# STC32G144K246 register map
Vendor: STC; File version: 2.0
Registers are 8-bit, read-write, no defined reset value unless marked. A register's access mark holds for its fields unless they carry their own. Offsets are from the block's base; [hi:lo] are bit positions; {n}, {i} and the like mark numbered series.

## GPIO9 — P9 端口、模式、上下拉和中断
Base 0x007EF701
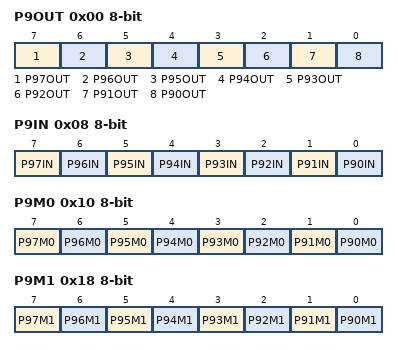
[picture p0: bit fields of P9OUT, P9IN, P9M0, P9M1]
0x00 P9OUT — P9端口输出寄存器
  [all] fields
    0=低电平; 1=高电平
  [7] P97OUT — 设置 P9.7 的输出缓冲区电平。实际输出行为由端口模式及外设复用共同决定。
  [6] P96OUT — 设置 P9.6 的输出缓冲区电平。实际输出行为由端口模式及外设复用共同决定。
  [5] P95OUT — 设置 P9.5 的输出缓冲区电平。实际输出行为由端口模式及外设复用共同决定。
  [4] P94OUT — 设置 P9.4 的输出缓冲区电平。实际输出行为由端口模式及外设复用共同决定。
  [3] P93OUT — 设置 P9.3 的输出缓冲区电平。实际输出行为由端口模式及外设复用共同决定。
  [2] P92OUT — 设置 P9.2 的输出缓冲区电平。实际输出行为由端口模式及外设复用共同决定。
  [1] P91OUT — 设置 P9.1 的输出缓冲区电平。实际输出行为由端口模式及外设复用共同决定。
  [0] P90OUT — 设置 P9.0 的输出缓冲区电平。实际输出行为由端口模式及外设复用共同决定。
0x08 P9IN ro — P9端口输入寄存器
  [all] fields
    0=低电平; 1=高电平
  [7] P97IN — 读取 P9.7 管脚上的实际电平。
  [6] P96IN — 读取 P9.6 管脚上的实际电平。
  [5] P95IN — 读取 P9.5 管脚上的实际电平。
  [4] P94IN — 读取 P9.4 管脚上的实际电平。
  [3] P93IN — 读取 P9.3 管脚上的实际电平。
  [2] P92IN — 读取 P9.2 管脚上的实际电平。
  [1] P91IN — 读取 P9.1 管脚上的实际电平。
  [0] P90IN — 读取 P9.0 管脚上的实际电平。
0x10 P9M0 — P9端口配置寄存器0
  [7] P97M0 — 控制 P9.7 的端口模式低位；与 P9M1.B7 配合设置，组合含义见下表。
  [6] P96M0 — 控制 P9.6 的端口模式低位；与 P9M1.B6 配合设置，组合含义见下表。
  [5] P95M0 — 控制 P9.5 的端口模式低位；与 P9M1.B5 配合设置，组合含义见下表。
  [4] P94M0 — 控制 P9.4 的端口模式低位；与 P9M1.B4 配合设置，组合含义见下表。
  [3] P93M0 — 控制 P9.3 的端口模式低位；与 P9M1.B3 配合设置，组合含义见下表。
  [2] P92M0 — 控制 P9.2 的端口模式低位；与 P9M1.B2 配合设置，组合含义见下表。
  [1] P91M0 — 控制 P9.1 的端口模式低位；与 P9M1.B1 配合设置，组合含义见下表。
  [0] P90M0 — 控制 P9.0 的端口模式低位；与 P9M1.B0 配合设置，组合含义见下表。
0x18 P9M1 — P9端口配置寄存器1
  [7] P97M1 — 控制 P9.7 的端口模式高位；与 P9M0.B7 配合设置，组合含义见下表。
  [6] P96M1 — 控制 P9.6 的端口模式高位；与 P9M0.B6 配合设置，组合含义见下表。
  [5] P95M1 — 控制 P9.5 的端口模式高位；与 P9M0.B5 配合设置，组合含义见下表。
  [4] P94M1 — 控制 P9.4 的端口模式高位；与 P9M0.B4 配合设置，组合含义见下表。
  [3] P93M1 — 控制 P9.3 的端口模式高位；与 P9M0.B3 配合设置，组合含义见下表。
  [2] P92M1 — 控制 P9.2 的端口模式高位；与 P9M0.B2 配合设置，组合含义见下表。
  [1] P91M1 — 控制 P9.1 的端口模式高位；与 P9M0.B1 配合设置，组合含义见下表。
  [0] P90M1 — 控制 P9.0 的端口模式高位；与 P9M0.B0 配合设置，组合含义见下表。
0x20 P9SETB wo write-1-sets — P9 输出置位命令。按位写 1 置位，写 0 不动作。固件写入已验证；Link1D SWD 直写可能改动其他位，请勿在调试器中写入。
0x28 P9CLRB wo write-1-clears — P9 输出清零命令。按位写 1 清零，写 0 不动作。固件写入已验证；Link1D SWD 直写可能改动其他位，请勿在调试器中写入。
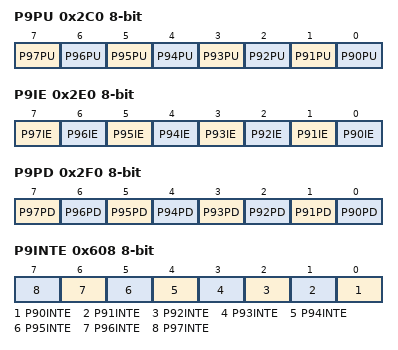
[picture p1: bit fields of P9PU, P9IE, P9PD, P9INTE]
0x2C0 P9PU — P9口上拉电阻控制寄存器
  [all] fields
    0=禁止内部上拉电阻; 1=使能内部上拉电阻
  [7] P97PU — 控制 P9.7 的内部上拉电阻。
  [6] P96PU — 控制 P9.6 的内部上拉电阻。
  [5] P95PU — 控制 P9.5 的内部上拉电阻。
  [4] P94PU — 控制 P9.4 的内部上拉电阻。
  [3] P93PU — 控制 P9.3 的内部上拉电阻。
  [2] P92PU — 控制 P9.2 的内部上拉电阻。
  [1] P91PU — 控制 P9.1 的内部上拉电阻。
  [0] P90PU — 控制 P9.0 的内部上拉电阻。
0x2E0 P9IE — P9口输入使能控制寄存器
  [all] fields
    0=禁止数字信号输入，用于模拟功能; 1=使能数字信号输入
  [7] P97IE — 控制 P9.7 的数字信号输入。
  [6] P96IE — 控制 P9.6 的数字信号输入。
  [5] P95IE — 控制 P9.5 的数字信号输入。
  [4] P94IE — 控制 P9.4 的数字信号输入。
  [3] P93IE — 控制 P9.3 的数字信号输入。
  [2] P92IE — 控制 P9.2 的数字信号输入。
  [1] P91IE — 控制 P9.1 的数字信号输入。
  [0] P90IE — 控制 P9.0 的数字信号输入。
0x2F0 P9PD — P9口下拉电阻控制寄存器
  [all] fields
    0=禁止内部下拉电阻; 1=使能内部下拉电阻
  [7] P97PD — 控制 P9.7 的内部下拉电阻。
  [6] P96PD — 控制 P9.6 的内部下拉电阻。
  [5] P95PD — 控制 P9.5 的内部下拉电阻。
  [4] P94PD — 控制 P9.4 的内部下拉电阻。
  [3] P93PD — 控制 P9.3 的内部下拉电阻。
  [2] P92PD — 控制 P9.2 的内部下拉电阻。
  [1] P91PD — 控制 P9.1 的内部下拉电阻。
  [0] P90PD — 控制 P9.0 的内部下拉电阻。
0x608 P9INTE — P9口中断使能寄存器
  [n-90] P{n}INTE (n=90..97) — 尚未自动匹配到此字段的独立说明；请查看下方章节说明。
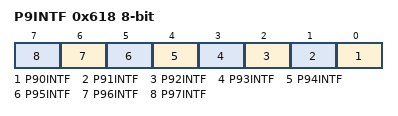
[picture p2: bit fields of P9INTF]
0x618 P9INTF ro — P9口中断标志寄存器
  [n-90] P{n}INTF (n=90..97) — 尚未自动匹配到此字段的独立说明；请查看下方章节说明。

## GPIOA — PA 端口、模式、上下拉和中断
Base 0x007EF702
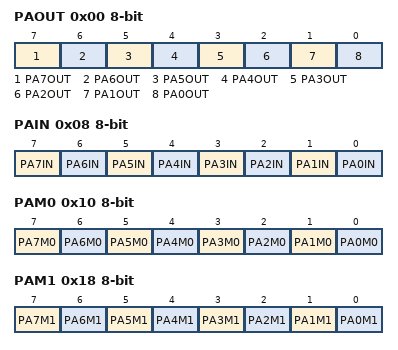
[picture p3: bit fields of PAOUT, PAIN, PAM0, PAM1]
0x00 PAOUT — PA端口输出寄存器
  [all] fields
    0=低电平; 1=高电平
  [7] PA7OUT — 设置 PA.7 的输出缓冲区电平。实际输出行为由端口模式及外设复用共同决定。
  [6] PA6OUT — 设置 PA.6 的输出缓冲区电平。实际输出行为由端口模式及外设复用共同决定。
  [5] PA5OUT — 设置 PA.5 的输出缓冲区电平。实际输出行为由端口模式及外设复用共同决定。
  [4] PA4OUT — 设置 PA.4 的输出缓冲区电平。实际输出行为由端口模式及外设复用共同决定。
  [3] PA3OUT — 设置 PA.3 的输出缓冲区电平。实际输出行为由端口模式及外设复用共同决定。
  [2] PA2OUT — 设置 PA.2 的输出缓冲区电平。实际输出行为由端口模式及外设复用共同决定。
  [1] PA1OUT — 设置 PA.1 的输出缓冲区电平。实际输出行为由端口模式及外设复用共同决定。
  [0] PA0OUT — 设置 PA.0 的输出缓冲区电平。实际输出行为由端口模式及外设复用共同决定。
0x08 PAIN ro — PA端口输入寄存器
  [all] fields
    0=低电平; 1=高电平
  [7] PA7IN — 读取 PA.7 管脚上的实际电平。
  [6] PA6IN — 读取 PA.6 管脚上的实际电平。
  [5] PA5IN — 读取 PA.5 管脚上的实际电平。
  [4] PA4IN — 读取 PA.4 管脚上的实际电平。
  [3] PA3IN — 读取 PA.3 管脚上的实际电平。
  [2] PA2IN — 读取 PA.2 管脚上的实际电平。
  [1] PA1IN — 读取 PA.1 管脚上的实际电平。
  [0] PA0IN — 读取 PA.0 管脚上的实际电平。
0x10 PAM0 — PA端口配置寄存器0
  [7] PA7M0 — 控制 PA.7 的端口模式低位；与 PAM1.B7 配合设置，组合含义见下表。
  [6] PA6M0 — 控制 PA.6 的端口模式低位；与 PAM1.B6 配合设置，组合含义见下表。
  [5] PA5M0 — 控制 PA.5 的端口模式低位；与 PAM1.B5 配合设置，组合含义见下表。
  [4] PA4M0 — 控制 PA.4 的端口模式低位；与 PAM1.B4 配合设置，组合含义见下表。
  [3] PA3M0 — 控制 PA.3 的端口模式低位；与 PAM1.B3 配合设置，组合含义见下表。
  [2] PA2M0 — 控制 PA.2 的端口模式低位；与 PAM1.B2 配合设置，组合含义见下表。
  [1] PA1M0 — 控制 PA.1 的端口模式低位；与 PAM1.B1 配合设置，组合含义见下表。
  [0] PA0M0 — 控制 PA.0 的端口模式低位；与 PAM1.B0 配合设置，组合含义见下表。
0x18 PAM1 — PA端口配置寄存器1
  [7] PA7M1 — 控制 PA.7 的端口模式高位；与 PAM0.B7 配合设置，组合含义见下表。
  [6] PA6M1 — 控制 PA.6 的端口模式高位；与 PAM0.B6 配合设置，组合含义见下表。
  [5] PA5M1 — 控制 PA.5 的端口模式高位；与 PAM0.B5 配合设置，组合含义见下表。
  [4] PA4M1 — 控制 PA.4 的端口模式高位；与 PAM0.B4 配合设置，组合含义见下表。
  [3] PA3M1 — 控制 PA.3 的端口模式高位；与 PAM0.B3 配合设置，组合含义见下表。
  [2] PA2M1 — 控制 PA.2 的端口模式高位；与 PAM0.B2 配合设置，组合含义见下表。
  [1] PA1M1 — 控制 PA.1 的端口模式高位；与 PAM0.B1 配合设置，组合含义见下表。
  [0] PA0M1 — 控制 PA.0 的端口模式高位；与 PAM0.B0 配合设置，组合含义见下表。
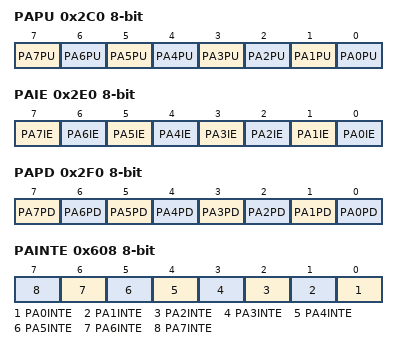
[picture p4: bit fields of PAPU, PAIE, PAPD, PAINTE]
0x2C0 PAPU — PA口上拉电阻控制寄存器
  [all] fields
    0=禁止内部上拉电阻; 1=使能内部上拉电阻
  [7] PA7PU — 控制 PA.7 的内部上拉电阻。
  [6] PA6PU — 控制 PA.6 的内部上拉电阻。
  [5] PA5PU — 控制 PA.5 的内部上拉电阻。
  [4] PA4PU — 控制 PA.4 的内部上拉电阻。
  [3] PA3PU — 控制 PA.3 的内部上拉电阻。
  [2] PA2PU — 控制 PA.2 的内部上拉电阻。
  [1] PA1PU — 控制 PA.1 的内部上拉电阻。
  [0] PA0PU — 控制 PA.0 的内部上拉电阻。
0x2E0 PAIE — PA口输入使能控制寄存器
  [all] fields
    0=禁止数字信号输入，用于模拟功能; 1=使能数字信号输入
  [7] PA7IE — 控制 PA.7 的数字信号输入。
  [6] PA6IE — 控制 PA.6 的数字信号输入。
  [5] PA5IE — 控制 PA.5 的数字信号输入。
  [4] PA4IE — 控制 PA.4 的数字信号输入。
  [3] PA3IE — 控制 PA.3 的数字信号输入。
  [2] PA2IE — 控制 PA.2 的数字信号输入。
  [1] PA1IE — 控制 PA.1 的数字信号输入。
  [0] PA0IE — 控制 PA.0 的数字信号输入。
0x2F0 PAPD — PA口下拉电阻控制寄存器
  [all] fields
    0=禁止内部下拉电阻; 1=使能内部下拉电阻
  [7] PA7PD — 控制 PA.7 的内部下拉电阻。
  [6] PA6PD — 控制 PA.6 的内部下拉电阻。
  [5] PA5PD — 控制 PA.5 的内部下拉电阻。
  [4] PA4PD — 控制 PA.4 的内部下拉电阻。
  [3] PA3PD — 控制 PA.3 的内部下拉电阻。
  [2] PA2PD — 控制 PA.2 的内部下拉电阻。
  [1] PA1PD — 控制 PA.1 的内部下拉电阻。
  [0] PA0PD — 控制 PA.0 的内部下拉电阻。
0x608 PAINTE — PA口中断使能寄存器
  [n] PA{n}INTE (n=0..7) — 尚未自动匹配到此字段的独立说明；请查看下方章节说明。
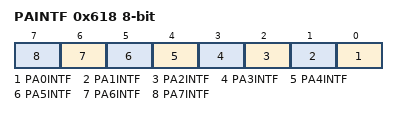
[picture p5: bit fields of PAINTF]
0x618 PAINTF ro — PA口中断标志寄存器
  [n] PA{n}INTF (n=0..7) — 尚未自动匹配到此字段的独立说明；请查看下方章节说明。
